# RA2A1 register map
Vendor: Renesas Electronics Corporation; Series: RA2; File version: 1.1
CPU: other r1p0, little endian, MPU, no FPU, VTOR, 2 interrupt priority bits
Registers are 8-bit, read-write, reset 0x0 unless marked. A register's access mark holds for its fields unless they carry their own. Offsets are from the block's base; [hi:lo] are bit positions; {n}, {i} and the like mark numbered series; 'fields as' and 'values as' point back to an identical list; <NAME> marks a mode.

## SYSTEM — System Control
Base 0x4001E000
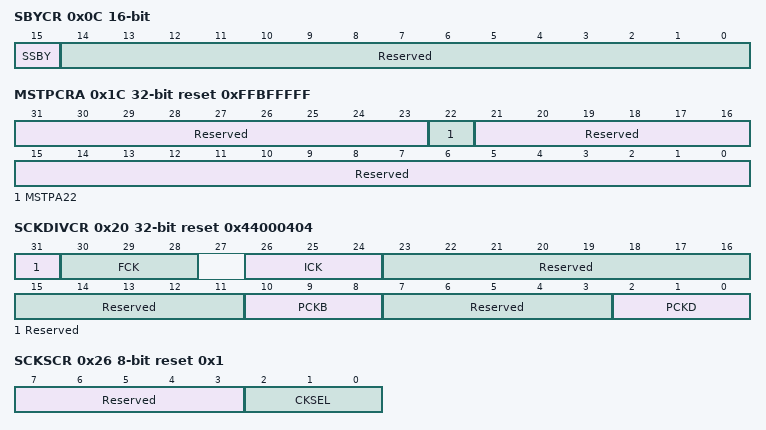
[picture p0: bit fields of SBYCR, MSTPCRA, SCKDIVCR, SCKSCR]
0x0C SBYCR 16-bit — Standby Control Register
  [15] SSBY — Software Standby
    0=Sleep Mode; 1=Software Standby Mode
  [14:0] Reserved — These bits are read as 000000000000000. The write value should be 000000000000000.
0x1C MSTPCRA 32-bit reset 0xFFBFFFFF — Module Stop Control Register A
  [31:23] Reserved — These bits are read as 111111111. The write value should be 111111111.
  [22] MSTPA22 — Data Transfer Controller Module Stop
    0=Cancel the module-stop state; 1=Enter the module-stop state
  [21:0] Reserved — These bits are read as 1111111111111111111111. The write value should be 1111111111111111111111.
0x20 SCKDIVCR 32-bit reset 0x44000404 — System Clock Division Control Register
  [31] Reserved — This bit is read as 0. The write value should be 0.
  [30:28] FCK — Flash IF Clock (FCLK) Select
    0=/1; 1=/2; 2=/4; 3=/8; 4=/16; 5=/32; 6=/64; other=others (Setting prohibited)
  [26:24] ICK — System Clock (ICLK) Select
    values as FCK
  [23:11] Reserved — These bits are read as 0000000000000. The write value should be 0000000000000.
  [10:8] PCKB — Peripheral Module Clock B (PCLKB) Select
    values as FCK
  [7:3] Reserved — These bits are read as 00000. The write value should be 00000.
  [2:0] PCKD — Peripheral Module Clock D (PCLKD) Select
    values as FCK
0x26 SCKSCR reset 0x1 — System Clock Source Control Register
  [7:3] Reserved — These bits are read as 00000. The write value should be 00000.
  [2:0] CKSEL — Clock Source Select
    0=HOCO; 1=MOCO; 2=LOCO; 3=Main clock oscillator; 4=Sub-clock oscillator; other=others (Setting prohibited)
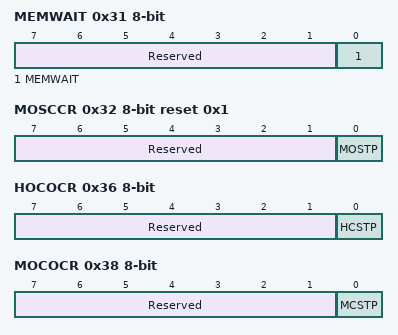
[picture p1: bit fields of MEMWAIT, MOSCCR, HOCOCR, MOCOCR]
0x31 MEMWAIT — Memory Wait Cycle Control Register
  [7:1] Reserved — These bits are read as 0000000. The write value should be 0000000.
  [0] MEMWAIT — Memory Wait Cycle Select
    0=No wait; 1=Wait
0x32 MOSCCR reset 0x1 — Main Clock Oscillator Control Register
  [7:1] Reserved — These bits are read as 0000000. The write value should be 0000000.
  [0] MOSTP — Main Clock Oscillator Stop
    0=Main clock oscillator is operating; 1=Main clock oscillator is stopped
0x36 HOCOCR (reset mask 0xFE) — High-Speed On-Chip Oscillator Control Register
  [7:1] Reserved — These bits are read as 0000000. The write value should be 0000000.
  [0] HCSTP — HOCO Stop
    0=HOCO is operating; 1=HOCO is stopped
0x38 MOCOCR — Middle-Speed On-Chip Oscillator Control Register
  [7:1] Reserved — These bits are read as 0000000. The write value should be 0000000.
  [0] MCSTP — MOCO Stop
    0=MOCO is operating; 1=MOCO is stopped
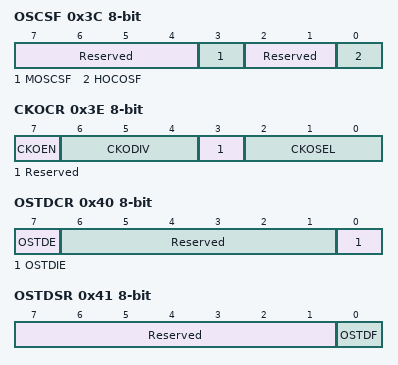
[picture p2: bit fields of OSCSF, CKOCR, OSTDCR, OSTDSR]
0x3C OSCSF ro (reset mask 0xFE) — Oscillation Stabilization Flag Register
  [7:4] Reserved — These bits are read as 0000.
  [3] MOSCSF — Main Clock Oscillation Stabilization Flag
    0=MOSTP = 1 (stopping the main clock oscillator) or oscillation of the main clock has not yet become stable; 1=Oscillation of the main clock is stable so the clock is available for use as the system clock
  [2:1] Reserved — These bits are read as 00.
  [0] HOCOSF — HOCO Clock Oscillation Stabilization FlagNOTE: The HOCOSF bit value after a reset is 1 when the OFS1.HOCOEN bit is 0. It is 0 when the OFS1.HOCOEN bit is 1.
    0=The HOCO clock is stopped or oscillation of the HOCO clock has not yet become stable; 1=Oscillation of the HOCO clock is stable so the clock is available for use as the system clock
0x3E CKOCR — Clock Out Control Register
  [7] CKOEN — Clock out enable
    0=Clock Out disable; 1=Clock Out enable
  [6:4] CKODIV — Clock out input frequency Division Select
    0=/1; 1=/2; 2=/4; 3=/8; 4=/16; 5=/32; 6=/64; 7=/128
  [3] Reserved — This bit is read as 0. The write value should be 0.
  [2:0] CKOSEL — Clock out source select
    0=HOCO; 1=MOCO; 2=LOCO; 3=MOSC; 4=SOSC; other=others (Setting prohibited)
0x40 OSTDCR — Oscillation Stop Detection Control Register
  [7] OSTDE — Oscillation Stop Detection Function Enable
    0=Oscillation stop detection function is disabled; 1=Oscillation stop detection function is enabled
  [6:1] Reserved — These bits are read as 000000. The write value should be 000000.
  [0] OSTDIE — Oscillation Stop Detection Interrupt Enable
    0=The oscillation stop detection interrupt is disabled. Oscillation stop detection is not notified to the POEG.; 1=The oscillation stop detection interrupt is enabled. Oscillation stop detection is notified to the POEG.
0x41 OSTDSR — Oscillation Stop Detection Status Register
  [7:1] Reserved — These bits are read as 0000000. The write value should be 0000000.
  [0] OSTDF write-0-clears read-modifies — Oscillation Stop Detection Flag
    0=The main clock oscillation stop has not been detected; 1=The main clock oscillation stop has been detected
0x61 MOCOUTCR — MOCO User Trimming Control Register
  [7:0] MOCOUTRM — MOCO User Trimming 1000_0000 : -128 1000_0001 : -127 1000_0010 : -126 . . . 1111_1111 : -1 0000_0000 : Center Code 0000_0001 : +1 . . . 0111_1101 : +125 0111_1110 : +126 0111_1111 : +127These bits are added to original MOCO trimming bits
0x62 HOCOUTCR — HOCO User Trimming Control Register
  [7:0] HOCOUTRM — HOCO User Trimming 1000_0000 : -128 1000_0001 : -127 1000_0010 : -126 . . . 1111_1111 : -1 0000_0000 : Center Code 0000_0001 : +1 . . . 0111_1101 : +125 0111_1110 : +126 0111_1111 : +127These bits are added to original HOCO trimming bits
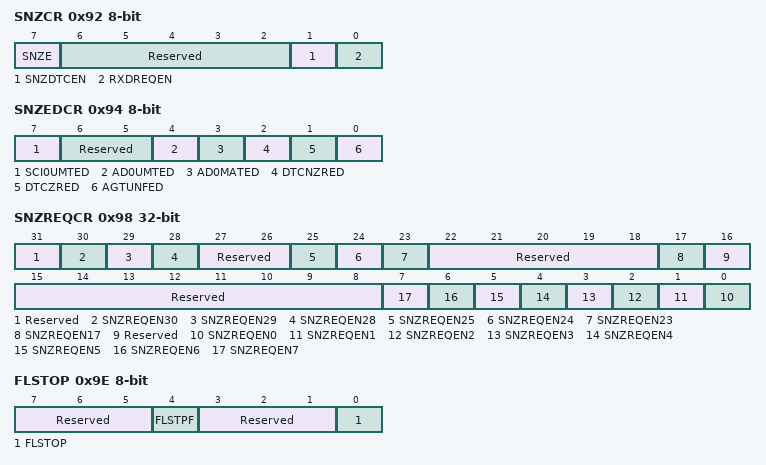
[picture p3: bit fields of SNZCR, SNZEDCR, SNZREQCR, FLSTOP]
0x92 SNZCR — Snooze Control Register
  [7] SNZE — Snooze Mode Enable
    0=Disable Snooze Mode; 1=Enable Snooze Mode
  [6:2] Reserved — These bits are read as 00000. The write value should be 00000.
  [1] SNZDTCEN — DTC Enable in Snooze Mode
    0=Disable DTC operation; 1=Enable DTC operation
  [0] RXDREQEN — RXD0 Snooze Request Enable NOTE: Do not set to 1 other than in asynchronous mode.
    0=Ignore RXD0 falling edge in Standby mode; 1=Accept RXD0 falling edge in Standby mode as a request to transit to Snooze mode
0x94 SNZEDCR — Snooze End Control Register
  [7] SCI0UMTED — SCI0 address unmatch Snooze End EnableNote: Do not set to 1 other than in asynchronous mode.
    0=Disable the Snooze End request; 1=Enable the Snooze End request
  [6:5] Reserved — These bits are read as 00. The write value should be 00.
  [4] AD0UMTED — AD compare mismatch 0 Snooze End Enable
    values as SCI0UMTED
  [3] AD0MATED — AD compare match 0 Snooze End Enable
    values as SCI0UMTED
  [2] DTCNZRED — Not Last DTC transmission completion Snooze End Enable
    values as SCI0UMTED
  [1] DTCZRED — Last DTC transmission completion Snooze End Enable
    values as SCI0UMTED
  [0] AGTUNFED — AGT1 underflow Snooze End Enable
    values as SCI0UMTED
0x98 SNZREQCR 32-bit — Snooze Request Control Register
  [31] Reserved — This bit is read as 0. The write value should be 0.
  [30] SNZREQEN30 — Snooze Request Enable 30Enable AGT1 compare match B snooze request
    0=Disable snooze request; 1=Enable snooze request
  [29] SNZREQEN29 — Snooze Request Enable 29Enable AGT1 compare match A snooze request
    0=Disable snooze request; 1=Enable snooze request
  [28] SNZREQEN28 — Snooze Request Enable 28Enable AGT1 underflow snooze request
    0=Disable snooze request; 1=Enable snooze request
  [27:26] Reserved — These bits are read as 00. The write value should be 00.
  [25] SNZREQEN25 — Snooze Request Enable 25Enable RTC period snooze request
    0=Disable snooze request; 1=Enable snooze request
  [24] SNZREQEN24 — Snooze Request Enable 24Enable RTC alarm snooze request
    0=Disable snooze request; 1=Enable snooze request
  [23] SNZREQEN23 — Snooze Request Enable 24Enable RTC alarm snooze request
    0=Disable snooze request; 1=Enable snooze request
  [22:18] Reserved — These bits are read as 00000. The write value should be 00000.
  [17] SNZREQEN17 — Snooze Request Enable 17Enable KINT snooze request
    0=Disable snooze request; 1=Enable snooze request
  [16:8] Reserved — These bits are read as 000000000. The write value should be 000000000.
  [n] SNZREQEN{n} (n=0..7) — Snooze Request Enable {n}Enable IRQ{n} pin snooze request
    0=Disable snooze request; 1=Enable snooze request
0x9E FLSTOP — Flash Operation Control Register
  [7:5] Reserved — These bits are read as 000. The write value should be 000.
  [4] FLSTPF ro — Flash Memory Operation Status Flag
    0=Transition completed; 1=During transition (from the flash-stop-status to flashoperating- status or vice versa)
  [3:1] Reserved — These bits are read as 000. The write value should be 000.
  [0] FLSTOP — Selecting ON/OFF of the Flash Memory Operation
    0=Code flash memory operates. Data flash memory operation depends on DFLCTL.DFLEN bit; 1=Code flash/Data flash memory stops
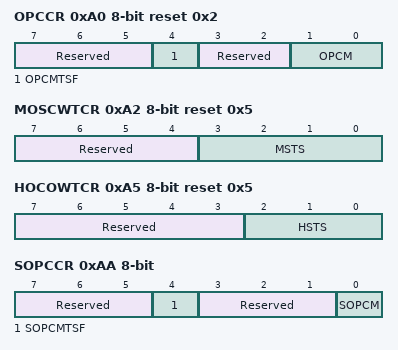
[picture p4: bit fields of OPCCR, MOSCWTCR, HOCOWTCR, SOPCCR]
0xA0 OPCCR reset 0x2 — Operating Power Control Register
  [7:5] Reserved — These bits are read as 000. The write value should be 000.
  [4] OPCMTSF ro — Operating Power Control Mode Transition Status Flag
    0=Transition completed; 1=During transition
  [3:2] Reserved — These bits are read as 00. The write value should be 00.
  [1:0] OPCM — Operating Power Control Mode Select
    0=High-speed mode; 1=Prohibited; 2=Prohibited; 3=Low-speed mode; other=others (Setting prohibited)
0xA2 MOSCWTCR reset 0x5 — Main Clock Oscillator Wait Control Register
  [7:4] Reserved — These bits are read as 0000. The write value should be 0000.
  [3:0] MSTS — Main clock oscillator wait time setting
    0=Wait time= 3 cycles (11.4us : calculated at LOCO=262.144KHz (3.81us TYP.)); 1=Wait time= 35 cycles (133.5us : calculated at LOCO=262.144KHz (3.81us TYP.)); 2=Wait time= 67 cycles (255.6us: calculated at LOCO=262.144KHz (3.81us TYP.)); 3=Wait time= 131 cycles (499.7us: calculated at LOCO=262.144KHz (3.81us TYP.)); 4=Wait time= 259 cycles (988.0us: calculated at LOCO=262.144KHz (3.81us TYP.)); 5=Wait time= 547 cycles (2086.6us: calculated at LOCO=262.144KHz (3.81us TYP.)); 6=Wait time= 1059 cycles (4039.8us: calculated at LOCO=262.144KHz (3.81us TYP.)); 7=Wait time= 2147 cycles (8190.2us: calculated at LOCO=262.144KHz (3.81us TYP.)); 8=Wait time= 4291 cycles (16368.9us: calculated at LOCO=262.144KHz (3.81us TYP.)); 9=Wait time= 8163 cycles (31139.4us: calculated at LOCO=262.144KHz (3.81us TYP.)); other=others (Setting prohibited)
0xA5 HOCOWTCR reset 0x5 — High-Speed On-Chip Oscillator Wait Control Register
  [7:3] Reserved — These bits are read as 00000. The write value should be 00000.
  [2:0] HSTS — HOCO wait time setting
    5=If HOCO frequency is other than 64MHz, should set the value to 101b; 6=If HOCO frequency = 64MHz, should set the value to 110b; other=others (Setting prohibited)
0xAA SOPCCR — Sub Operating Power Control Register
  [7:5] Reserved — These bits are read as 000. The write value should be 000.
  [4] SOPCMTSF ro — Sub Operating Power Control Mode Transition Status Flag
    0=Transition completed; 1=During transition
  [3:1] Reserved — These bits are read as 000. The write value should be 000.
  [0] SOPCM — Sub Operating Power Control Mode Select
    0=Other than Subosc-speed mode; 1=Subosc-speed mode
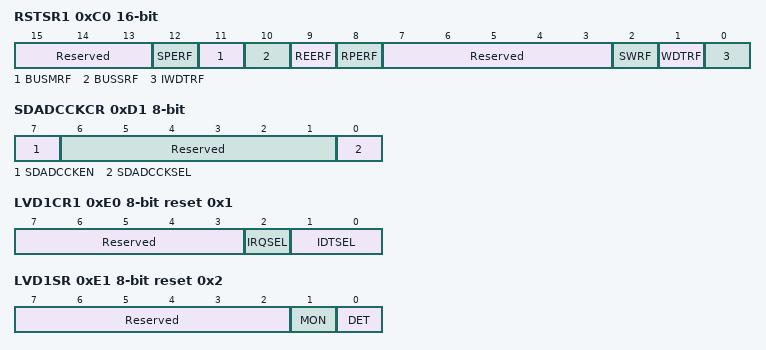
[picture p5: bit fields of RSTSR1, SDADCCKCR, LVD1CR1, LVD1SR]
0xC0 RSTSR1 16-bit (reset mask 0xE0F8) — Reset Status Register 1
  [15:13] Reserved — These bits are read as 000. The write value should be 000.
  [12] SPERF write-0-clears read-modifies — SP Error Reset Detect FlagNote: Only 0 can be written to clear the flag. The reset flag must be written as 0 after the reset flag is read as 1.
    0=SP error reset not detected; 1=SP error reset detected
  [11] BUSMRF write-0-clears read-modifies — Bus Master MPU Reset Detect FlagNote: Only 0 can be written to clear the flag. The reset flag must be written as 0 after the reset flag is read as 1.
    0=Bus Master MPU reset not detected; 1=Bus Master MPU reset detected
  [10] BUSSRF write-0-clears read-modifies — Bus Slave MPU Reset Detect FlagNote: Only 0 can be written to clear the flag. The reset flag must be written as 0 after the reset flag is read as 1.
    0=Bus Slave MPU reset not detected; 1=Bus Slave MPU reset detected
  [9] REERF write-0-clears read-modifies — RAM ECC Error Reset Detect FlagNote: Only 0 can be written to clear the flag. The reset flag must be written as 0 after the reset flag is read as 1.
    0=RAM ECC error reset not detected; 1=RAM ECC error reset detected
  [8] RPERF write-0-clears read-modifies — RAM Parity Error Reset Detect FlagNote: Only 0 can be written to clear the flag. The reset flag must be written as 0 after the reset flag is read as 1.
    0=RAM parity error reset not detected; 1=RAM parity error reset detected
  [7:3] Reserved — These bits are read as 00000. The write value should be 00000.
  [2] SWRF write-0-clears read-modifies — Software Reset Detect FlagNote: Only 0 can be written to clear the flag. The reset flag must be written as 0 after the reset flag is read as 1.
    0=Software reset not detected; 1=Software reset detected
  [1] WDTRF write-0-clears read-modifies — Watchdog Timer Reset Detect FlagNote: Only 0 can be written to clear the flag. The reset flag must be written as 0 after the reset flag is read as 1.
    0=Watchdog timer reset not detected; 1=Watchdog timer reset detected
  [0] IWDTRF write-0-clears read-modifies — Independent Watchdog Timer Reset Detect FlagNote: Only 0 can be written to clear the flag. The reset flag must be written as 0 after the reset flag is read as 1.
    0=Independent watchdog timer reset not detected; 1=Independent watchdog timer reset detected
0xD1 SDADCCKCR — 24-bit Sigma-Delta A/D Converter Clock Control Register
  [7] SDADCCKEN — 24-bit Sigma-Delta A/D Converter Clock Select
    0=MOSC is chosen by a source clock of 24-bit Sigma-Delta A/D Converter Clock; 1=HOCO is chosen by a source clock of 24-bit Sigma-Delta A/D Converter Clock
  [6:1] Reserved — These bits are read as 000000. The write value should be 000000.
  [0] SDADCCKSEL — 24-bit Sigma-Delta A/D Converter Clock Enable
    0=24-bit Sigma-Delta A/D Converter Clock is disabled; 1=24-bit Sigma-Delta A/D Converter Clock is enabled
0xE0 LVD1CR1 reset 0x1 — Voltage Monitor 1 Circuit Control Register 1
  [7:3] Reserved — These bits are read as 00000. The write value should be 00000.
  [2] IRQSEL — Voltage Monitor 1 Interrupt Type Select
    0=Non-maskable interrupt; 1=Maskable interrupt
  [1:0] IDTSEL — Voltage Monitor 1 Interrupt Generation Condition Select
    0=When VCC>=Vdet1 (rise) is detected; 1=When VCC<Vdet1 (drop) is detected; 2=When drop and rise are detected; 3=Settings prohibited
0xE1 LVD1SR reset 0x2 — Voltage Monitor 1 Circuit Status Register
  [7:2] Reserved — These bits are read as 000000. The write value should be 000000.
  [1] MON ro — Voltage Monitor 1 Signal Monitor Flag
    0=VCC < Vdet1; 1=VCC >= Vdet1 or MON is disabled
  [0] DET write-0-clears read-modifies — Voltage Monitor 1 Voltage Change Detection Flag
    0=Not detected; 1=Vdet1 passage detection
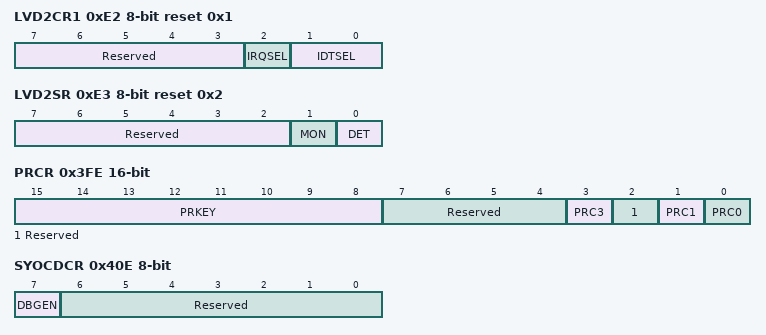
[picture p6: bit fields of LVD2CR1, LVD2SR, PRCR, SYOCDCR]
0xE2 LVD2CR1 reset 0x1 — Voltage Monitor 2 Circuit Control Register 1
  [7:3] Reserved — These bits are read as 00000. The write value should be 00000.
  [2] IRQSEL — Voltage Monitor 2 Interrupt Type Select
    0=Non-maskable interrupt; 1=Maskable interrupt
  [1:0] IDTSEL — Voltage Monitor 2 Interrupt Generation Condition Select
    0=When VCC>=Vdet2 (rise) is detected; 1=When VCC<Vdet2 (drop) is detected; 2=When drop and rise are detected; 3=Settings prohibited
0xE3 LVD2SR reset 0x2 — Voltage Monitor 2 Circuit Status Register
  [7:2] Reserved — These bits are read as 000000. The write value should be 000000.
  [1] MON ro — Voltage Monitor 2 Signal Monitor Flag
    0=VCC < Vdet2; 1=VCC >= Vdet2 or MON is disabled
  [0] DET write-0-clears read-modifies — Voltage Monitor 2 Voltage Change Detection Flag
    0=Not detected; 1=Vdet2 passage detection
0x3FE PRCR 16-bit — Protect Register
  [15:8] PRKEY wo — PRKEY Key Code
    90=Enables writing to the PRCR register; other=others (Disables writing to the PRCR register.)
  [7:4] Reserved — These bits are read as 0000. The write value should be 0000.
  [3] PRC3 — Enables writing to the registers related to the LVD.
    0=Writes protected; 1=Writes not protected
  [2] Reserved — This bit is read as 0. The write value should be 0.
  [1] PRC1 — Enables writing to the registers related to the operating modes, the low power consumption modes and the battery backup function.
    0=Writes protected; 1=Writes not protected
  [0] PRC0 — Enables writing to the registers related to the clock generation circuit.
    0=Writes protected; 1=Writes not protected
0x40E SYOCDCR — System Control OCD Control Register
  [7] DBGEN write-0-clears read-modifies — Debugger Enable
    0=On-chip debugger is disabled; 1=On-chip debugger is enabled
  [6:0] Reserved — These bits are read as 0000000. The write value should be 0000000.
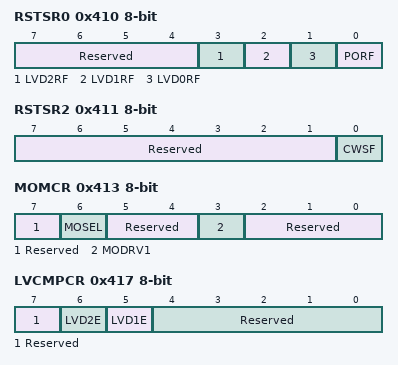
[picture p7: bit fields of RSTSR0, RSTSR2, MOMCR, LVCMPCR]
0x410 RSTSR0 (reset mask 0xF0) — Reset Status Register 0
  [7:4] Reserved — These bits are read as 0000. The write value should be 0000.
  [3] LVD2RF write-0-clears read-modifies — Voltage Monitor 2 Reset Detect FlagNote: Only 0 can be written to clear the flag. The reset flag must be written with 0 after the reset flag is read as 1.
    0=Voltage Monitor 2 reset not detected; 1=Voltage Monitor 2 reset detected
  [2] LVD1RF write-0-clears read-modifies — Voltage Monitor 1 Reset Detect FlagNote: Only 0 can be written to clear the flag. The reset flag must be written with 0 after the reset flag is read as 1.
    0=Voltage Monitor 1 reset not detected; 1=Voltage Monitor 1 reset detected
  [1] LVD0RF write-0-clears read-modifies — Voltage Monitor 0 Reset Detect FlagNote: Only 0 can be written to clear the flag. The reset flag must be written with 0 after the reset flag is read as 1.
    0=Voltage Monitor 0 reset not detected; 1=Voltage Monitor 0 reset detected
  [0] PORF write-0-clears read-modifies — Power-On Reset Detect FlagNote: Only 0 can be written to clear the flag. The reset flag must be written with 0 after the reset flag is read as 1.
    0=Power-on reset not detected; 1=Power-on reset detected
0x411 RSTSR2 (reset mask 0xFE) — Reset Status Register 2
  [7:1] Reserved — These bits are read as 0000000. The write value should be 0000000.
  [0] CWSF write-1-sets read-modifies — Cold/Warm Start Determination FlagNote: Only 1 can be written to set the flag.
    0=Cold start; 1=Warm start
0x413 MOMCR — Main Clock Oscillator Mode Oscillation Control Register
  [7] Reserved — This bit is read as 0. The write value should be 0.
  [6] MOSEL — Main Clock Oscillator Switching
    0=Resonator; 1=External clock input
  [5:4] Reserved — These bits are read as 00. The write value should be 00.
  [3] MODRV1 — Main Clock Oscillator Drive Capability 1 Switching
    0=10 MHz to 20 MHz; 1=1 MHz to 10 MHz
  [2:0] Reserved — These bits are read as 000. The write value should be 000.
0x417 LVCMPCR — Voltage Monitor Circuit Control Register
  [7] Reserved — This bit is read as 0. The write value should be 0.
  [6] LVD2E — Voltage Detection 2 Enable
    0=Voltage detection 2 circuit disabled; 1=Voltage detection 2 circuit enabled
  [5] LVD1E — Voltage Detection 1 Enable
    0=Voltage detection 1 circuit disabled; 1=Voltage detection 1 circuit enabled
  [4:0] Reserved — These bits are read as 00000. The write value should be 00000.
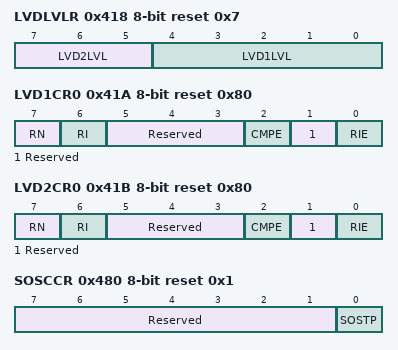
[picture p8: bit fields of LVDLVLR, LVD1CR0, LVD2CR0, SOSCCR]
0x418 LVDLVLR reset 0x7 — Voltage Detection Level Select Register
  [7:5] LVD2LVL — Voltage Detection 2 Level Select (Standard voltage during drop in voltage)
    0=4.29V(Vdet2_0); 1=4.14V(Vdet2_1); 2=4.02V(Vdet2_2); 3=3.84V(Vdet2_3); other=others (Settingprohibited)
  [4:0] LVD1LVL — Voltage Detection 1 Level Select (Standard voltage during drop in voltage)
    0=4.29V(Vdet1_0); 1=4.14V(Vdet1_1); 2=4.02V(Vdet1_2); 3=3.84V(Vdet1_3); 4=3.10V(Vdet1_4); 5=3.00V(Vdet1_5); 6=2.90V(Vdet1_6); 7=2.79V(Vdet1_7); 8=2.68V(Vdet1_8); 9=2.58V(Vdet1_9); 10=2.48V(Vdet1_A); 11=2.20V(Vdet1_B); 12=1.96V(Vdet1_C); 13=1.86V(Vdet1_D); 14=1.75V(Vdet1_E); 15=1.65V(Vdet1_F); other=others (Setting prohibited.)
0x41A LVD1CR0 reset 0x80 (reset mask 0xF7) — Voltage Monitor 1 Circuit Control Register 0
  [7] RN — Voltage Monitor 1 Reset Negate Select
    0=Negation follows a stabilization time (tLVD1) after VCC > Vdet1 is detected; 1=Negation follows a stabilization time (tLVD1) after assertion of the LVD1 reset
  [6] RI — Voltage Monitor 1 Circuit Mode Select
    0=Voltage monitor 1 interrupt during Vdet1 passage; 1=Voltage monitor 1 reset enabled when the voltage falls to and below Vdet1
  [5:3] Reserved — These bits are read as 000. The write value should be 000.
  [2] CMPE — Voltage Monitor 1 Circuit Comparison Result Output Enable
    0=Voltage monitor 1 circuit comparison result output disabled; 1=Voltage monitor 1 circuit comparison result output enabled
  [1] Reserved — This bit is read as 0. The write value should be 0.
  [0] RIE — Voltage Monitor 1 Interrupt/ Reset Enable
    0=Disabled; 1=Enabled
0x41B LVD2CR0 reset 0x80 (reset mask 0xF7) — Voltage Monitor 2 Circuit Control Register 0
  [7] RN — Voltage Monitor 2 Reset Negate Select
    0=Negation follows a stabilization time (tLVD2) after VCC > Vdet2 is detected; 1=Negation follows a stabilization time (tLVD2) after assertion of the LVD2 reset
  [6] RI — Voltage Monitor 2 Circuit Mode Select
    0=Voltage monitor 2 interrupt during Vdet2 passage; 1=Voltage monitor 2 reset enabled when the voltage falls to and below Vdet2
  [5:3] Reserved — These bits are read as 000. The write value should be 000.
  [2] CMPE — Voltage Monitor 2 Circuit Comparison Result Output Enable
    0=Voltage monitor 2 circuit comparison result output disabled; 1=Voltage monitor 2 circuit comparison result output enabled
  [1] Reserved — This bit is read as 0. The write value should be 0.
  [0] RIE — Voltage Monitor 2 Interrupt/Reset Enable
    0=Disabled; 1=Enabled
0x480 SOSCCR reset 0x1 — Sub-clock Oscillator Control Register
  [7:1] Reserved — These bits are read as 0000000. The write value should be 0000000.
  [0] SOSTP — Sub-Clock Oscillator Stop
    0=Sub-clock oscillator is operating; 1=Sub-clock oscillator is stopped
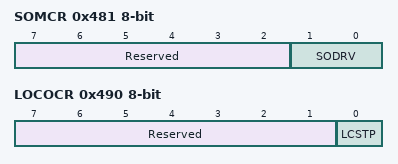
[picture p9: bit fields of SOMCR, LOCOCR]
0x481 SOMCR — Sub-clock Oscillator Mode Control Register
  [7:2] Reserved — These bits are read as 000000. The write value should be 000000.
  [1:0] SODRV — Sub Clock Oscillator Drive Capability Switching
    0=Normal Mode; 1=Low power mode 1; 2=Low power mode 2; 3=Low power mode 3
0x490 LOCOCR — Low-Speed On-Chip Oscillator Control Register
  [7:1] Reserved — These bits are read as 0000000. The write value should be 0000000.
  [0] LCSTP — LOCO Stop
    0=LOCO is operating; 1=LOCO is stopped
0x492 LOCOUTCR — LOCO User Trimming Control Register
  [7:0] LOCOUTRM — LOCO User Trimming 1000_0000 : -128 1000_0001 : -127 1000_0010 : -126 . . . 1111_1111 : -1 0000_0000 : Center Code 0000_0001 : +1 . . . 0111_1101 : +125 0111_1110 : +126 0111_1111 : +127These bits are added to original LOCO trimming bits
